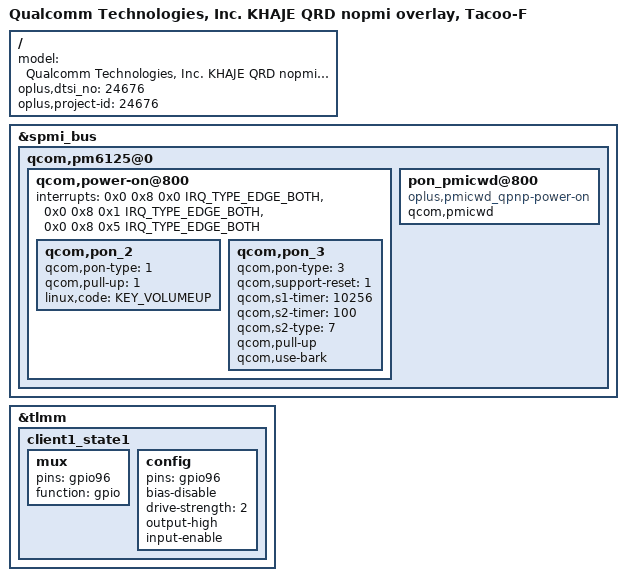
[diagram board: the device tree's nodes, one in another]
/dts-v1/;
/plugin/;

#include "../qcom/khaje-qrd-nopmi-overlay.dts"
#include "khaje_overlay_common.dtsi"
#include "Tacoo-F_overlay_common.dtsi"
#include "nfc/TacooF-nfc-pn560.dtsi"
#include "sensor/Tacoo-F-24676-sensor-mtp.dtsi"
#include "oplus_chg/oplus-chg-24675-24676.dtsi"
#include "oplus_chg/oplus-chg-24675-pps.dtsi"

/ {
    model = "Qualcomm Technologies, Inc. KHAJE QRD nopmi overlay, Tacoo-F";
    oplus,dtsi_no = <24676>;
    oplus,project-id = <24676>;
};

&spmi_bus {
	qcom,pm6125@0 {
		qcom,power-on@800 {
			interrupts = <0x0 0x8 0x0 IRQ_TYPE_EDGE_BOTH>,
						 <0x0 0x8 0x1 IRQ_TYPE_EDGE_BOTH>,
						 <0x0 0x8 0x5 IRQ_TYPE_EDGE_BOTH>;
			interrupt-names = "kpdpwr", "resin", "kpdpwr-resin-bark";

			qcom,pon_2 {
				qcom,pon-type = <1>;
				qcom,pull-up = <1>;
				linux,code = <KEY_VOLUMEUP>;
			};

			qcom,pon_3 {
				qcom,pon-type = <3>;
				qcom,support-reset = <1>;
				qcom,s1-timer = <10256>;
				qcom,s2-timer = <100>;
				qcom,s2-type = <7>;
				qcom,pull-up;
				qcom,use-bark;
			};
		};

		pon_pmicwd@800 {
			compatible = "oplus,pmicwd_qpnp-power-on";
			qcom,pmicwd;
		};
	};
};

&tlmm {
	client1_state1:client1_state1 {
		mux {
			pins = "gpio96";
			function = "gpio";
		};
		config {
			pins = "gpio96";
			bias-disable;
			drive-strength = <2>;
			output-high;
			input-enable;
		};
	};
};
